# STM32MP21_CM33 register map
File version: 0.4
CPU: CM33 r0p1, little endian, MPU, FPU, vendor SysTick, 8 interrupt priority bits
Registers are 32-bit, read-write, reset 0x0 unless marked. A register's access mark holds for its fields unless they carry their own. Offsets are from the block's base; [hi:lo] are bit positions; lines under a group give offsets from that group; {n}, {i} and the like mark numbered series.

## CRC — CRC address block description
Base 0x404C0000
Same registers: CRC_S 0x504C0000
0x00 CRC_DR reset 0xFFFFFFFF — CRC data register
  [31:0] DR — Data register bits
0x04 CRC_IDR — CRC independent data register
  [31:0] IDR — General-purpose 32-bit data register bits
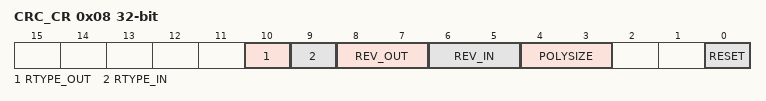
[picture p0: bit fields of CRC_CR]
0x08 CRC_CR — CRC control register
  [10] RTYPE_OUT — Reverse type output
    0=Bit level output; 1=Byte or half-word level output
  [9] RTYPE_IN — Reverse type input
    0=Bit level input; 1=Byte or half-word level input
  [8:7] REV_OUT — Reverse output data
    0=Bit order not affected (RTYPE_OUT=0 or 1); 1=Bit-reversed output format (RTYPE_OUT=0) or half-word reversal done by word (RTYPE_OUT=1); 2=Bit order not affected (RTYPE_OUT=0) or byte reversal done by word (RTYPE_OUT=1); 3=Bit order not affected (RTYPE_OUT=0 or 1)
  [6:5] REV_IN — Reverse input data
    0=Bit order not affected (RTYPE_IN=0 or 1); 1=Bit reversal done by byte (RTYPE_IN=0) or half-word reversal done by word (RTYPE_IN=1); 2=Bit reversal done by half-word (RTYPE_IN=0) or byte reversal done by word (RTYPE_IN=1); 3=Bit reversal done by word (RTYPE_IN=0) or bit order is not affected (RTYPE_IN=1)
  [4:3] POLYSIZE — Polynomial size
    0=32 bit polynomial; 1=16 bit polynomial; 2=8 bit polynomial; 3=7 bit polynomial
  [0] RESET — RESET bit
0x10 CRC_INIT reset 0xFFFFFFFF — CRC initial value
  [31:0] CRC_INIT — Programmable initial CRC value
0x14 CRC_POL reset 0x4C11DB7 — CRC polynomial
  [31:0] POL — Programmable polynomial

## DDRPERFM — DDRPERFM register block
Base 0x480C0000
Same registers: DDRPERFM_S 0x580C0000
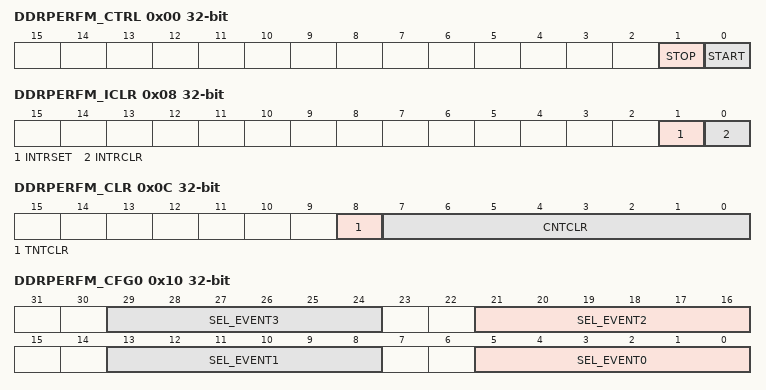
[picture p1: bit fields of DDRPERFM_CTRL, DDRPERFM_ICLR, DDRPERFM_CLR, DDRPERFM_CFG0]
0x00 DDRPERFM_CTRL — DDRPERFM control register
  [1] STOP — Writing 1 stops all counters.
  [0] START — Writing 1 starts all counters.
0x04 DDRPERFM_IMSK — DDRPERFM interrupt mask register
  [0] INTRMSK
    0=No effect; 1=DDRPERFM interruption signal masked
0x08 DDRPERFM_ICLR — DDRPERFM interrupt clear register
  [1] INTRSET
    0=No effect; 1=Set the interruption signal when asserted
  [0] INTRCLR — Note: The counters must be cleared first (to remove the interruption condition) before the interruption is cleared.
    0=No effect; 1=Clear the interruption signal when asserted
0x0C DDRPERFM_CLR — DDRPERFM counter clear register
  [8] TNTCLR — Note: Setting this bit is ignored if BUSY = 1 in DDRPERFM_STATUS.
    0=No effect; 1=Clear free running counter and associated status bits (timeout and overflow indicators)
  [7:0] CNTCLR — Note: Setting this bit is ignored if BUSY = 1 in DDRPERFM_STATUS.
    0=No effect; 1=Clear corresponding counters and associated status bits (timeout and overflow indicators)
0x10 DDRPERFM_CFG0 — DDRPERFM configuration register 0
  [8n+5:8n] SEL_EVENT{n} (n=0..3) — Selection of the performance logging signal to be monitored by the event counter {n}
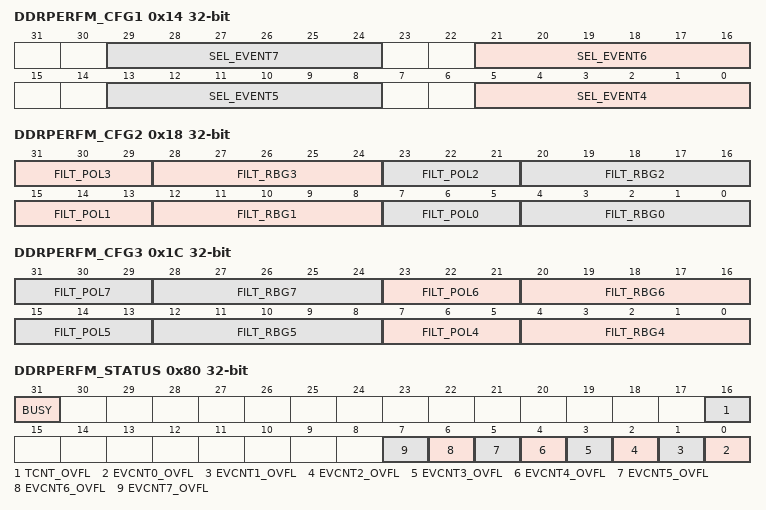
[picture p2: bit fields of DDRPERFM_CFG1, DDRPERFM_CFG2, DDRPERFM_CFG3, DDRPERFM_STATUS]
0x14 DDRPERFM_CFG1 — DDRPERFM configuration register 1
  [8n-27:8n-32] SEL_EVENT{n} (n=4..7) — Selection of the performance logging signal to be monitored by the event counter {n}
0x18 DDRPERFM_CFG2 — DDRPERFM configuration register 2
  [31:29] FILT_POL3 — Selection of the performance logging signal to be monitored by the event counter 3
  [8n+4:8n] FILT_RBG{n} (n=0..3) — Configuration of the rank/bank/bank group filtering for the event counter {n} based on FILT_POL{n} value
  [23:21] FILT_POL2 — Filtering policy for the event counter 2.
  [15:13] FILT_POL1 — Filtering policy for the event counter 1 (refer to Table76)
  [7:5] FILT_POL0 — Filtering policy for the event counter 0 (refer to Table76)
0x1C DDRPERFM_CFG3 — DDRPERFM configuration register 3
  [8n-25:8n-27] FILT_POL{n} (n=4..7) — Filtering policy for the event counter {n} (refer to Table76)
  [8n-28:8n-32] FILT_RBG{n} (n=4..7) — Configuration of the rank/bank/bank group filtering for the event counter {n} based on FILT_POL{n} value
0x20 DDRPERFM_CFG4 reset 0xFFFFFFFF — DDRPERFM configuration register 4
  [31:0] TIME_OUT — Timeout value for the time counter
0x24 DDRPERFM_CFG5 — DDRPERFM event counter enable register
  [7:0] EVCNT_EN — Event counter enable
0x28 DDRPERFM_DRAMINF — DDRPERFM DRAM information register
  [1:0] DRAM_TYPE — DRAM information used for DFI decoding
    0=LPDDR4; 1=LPDDR3; 2=DDR4; 3=DDR3
{0x40+4i} DDRPERFM_EVCNT{i} ro (i=0..7) — DDRPERFM event counter {i} register
  [31:0] EVCNT{i} — Counter value for event {i}
0x60 DDRPERFM_TCNT ro — DDRPERFM time counter register
  [31:0] TCNT — Time counter value
0x80 DDRPERFM_STATUS ro
  [31] BUSY — Real-time busy indicator
  [16] TCNT_OVFL — When read to 1, the DDRPERFM is stopped due to time counter reaching the timeout value.
  [n] EVCNT{n}_OVFL (n=0..7) — When read to 1, the DDRPERFM is stopped due to event counter {n} overflow.
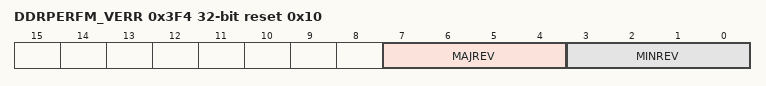
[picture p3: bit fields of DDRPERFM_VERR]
0x3F4 DDRPERFM_VERR ro reset 0x10 — DDRPERFM version register
  [7:4] MAJREV — DDRPERFM major revision
  [3:0] MINREV — DDRPERFM minor revision
0x3F8 DDRPERFM_ID ro reset 0x140061 — DDRPERFM identification register
  [31:0] ID — DDRPERFM unique identification
0x3FC DDRPERFM_SID ro reset 0xA3C5DD01 — DDRPERFM magic ID register
  [31:0] SID — Magic ID for automatic DDRPERFM discovery
